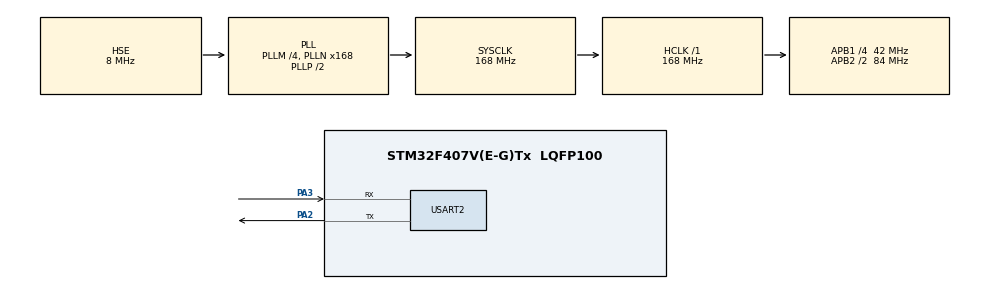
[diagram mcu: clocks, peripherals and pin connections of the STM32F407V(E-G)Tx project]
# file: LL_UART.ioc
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Mcu.Family=STM32F4
Mcu.Name=STM32F407V(E-G)Tx
Mcu.Package=LQFP100
NVIC.PriorityGroup=NVIC_PRIORITYGROUP_4
NVIC.USART2_IRQn=true\:0\:0\:false\:false\:true\:true\:true\:true
PA2.Mode=Asynchronous
PA2.Signal=USART2_TX
PA3.Mode=Asynchronous
PA3.Signal=USART2_RX
PH0-OSC_IN.Mode=HSE-External-Oscillator
PH0-OSC_IN.Signal=RCC_OSC_IN
PH1-OSC_OUT.Mode=HSE-External-Oscillator
PH1-OSC_OUT.Signal=RCC_OSC_OUT
ProjectManager.HeapSize=0x200
ProjectManager.StackSize=0x400
ProjectManager.TargetToolchain=STM32CubeIDE
RCC.48MHZClocksFreq_Value=84000000
RCC.AHBFreq_Value=168000000
RCC.APB1CLKDivider=RCC_HCLK_DIV4
RCC.APB1Freq_Value=42000000
RCC.APB1TimFreq_Value=84000000
RCC.APB2CLKDivider=RCC_HCLK_DIV2
RCC.APB2Freq_Value=84000000
RCC.APB2TimFreq_Value=168000000
RCC.CortexFreq_Value=168000000
RCC.HCLKFreq_Value=168000000
RCC.HSE_VALUE=8000000
RCC.HSI_VALUE=16000000
RCC.LSE_VALUE=32768
RCC.PLLM=4
RCC.PLLN=168
RCC.PLLSourceVirtual=RCC_PLLSOURCE_HSE
RCC.SYSCLKFreq_VALUE=168000000
RCC.SYSCLKSource=RCC_SYSCLKSOURCE_PLLCLK
RCC.VCOOutputFreq_Value=336000000
USART2.VirtualMode=VM_ASYNC
board=custom

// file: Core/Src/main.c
/* USER CODE BEGIN Header */
/**
  ******************************************************************************
  * @file           : main.c
  * @brief          : Main program body
  ******************************************************************************
  * @attention
  *
  * Copyright (c) 2023 STMicroelectronics.
  * All rights reserved.
  *
  * This software is licensed under terms that can be found in the LICENSE file
  * in the root directory of this software component.
  * If no LICENSE file comes with this software, it is provided AS-IS.
  *
  ******************************************************************************
  */
/* USER CODE END Header */
#include "main.h"
#include "usart.h"
#include "gpio.h"

/* USER CODE BEGIN Includes */
#include <stdio.h>
#include <string.h>
#include <lwrb.h>
#include <circularuart.h>
/* USER CODE END Includes */

/* USER CODE BEGIN PM */
#define RX_BUFFER_SIZE		30
#define TX_BUFFER_SIZE		100
/* USER CODE END PM */

/* USER CODE BEGIN PV */
uint8_t rx_buffer[RX_BUFFER_SIZE];
uint8_t	tx_buffer[TX_BUFFER_SIZE];
rbuart_t rb_tx;
rbuart_t rb_rx;
/* USER CODE END PV */

void SystemClock_Config(void);

/* USER CODE BEGIN 0 */
uint8_t UART2_SendData(uint8_t *pDta, uint32_t len, uint32_t timeout){
	uint32_t tickStar = HAL_GetTick();
	while((HAL_GetTick() - tickStar) < timeout){
		//verificar
		if(USART2->SR & USART_SR_TXE){
			//Eviar dato
			LL_USART_TransmitData8(USART2, *pDta);
			pDta++;
			len--;
		}
		if(len ==  0){
			return 0;
		}
	}
	return 1;
}

/* USER CODE END 0 */

int main(void)
{
  /* USER CODE BEGIN 1 */
	uint8_t txt[100];
	uint8_t rx[10];

  /* USER CODE END 1 */

  /* MCU Configuration--------------------------------------------------------*/

  /* Reset of all peripherals, Initializes the Flash interface and the Systick. */
  HAL_Init();

  /* Configure the system clock */
  SystemClock_Config();

  /* Initialize all configured peripherals */
  MX_GPIO_Init();
  MX_USART2_UART_Init();
  /* USER CODE BEGIN 2 */
  sprintf((char*)txt, "probando funcion\r\n");
//  UART2_SendData(txt, strlen((char*)txt), 1000);
  rbuart_init(&rb_tx, USART2, tx_buffer, TX_BUFFER_SIZE);
  rbuart_init(&rb_rx, USART2, rx_buffer, RX_BUFFER_SIZE);

  rbuart_send(&rb_tx, txt, strlen((char*)txt));
  rbuart_start_receive(&rb_rx);
  /* USER CODE END 2 */

  /* Infinite loop */
  while (1)
  {

    /* USER CODE BEGIN 3 */
	  if(rbuart_get_receiveSize(&rb_rx) >= 10){
		  rbuart_get_data(&rb_rx, rx, 5);
		  memset(txt, 0, 100);
		  sprintf((char*)txt, "datos recibidos->%s\r\n", rx);
		  rbuart_send(&rb_tx, txt, strlen((char*)txt));
	  }
  }
  /* USER CODE END 3 */
}

void SystemClock_Config(void)
{
  RCC_OscInitTypeDef RCC_OscInitStruct = {0};
  RCC_ClkInitTypeDef RCC_ClkInitStruct = {0};

  /** Configure the main internal regulator output voltage
  */
  __HAL_RCC_PWR_CLK_ENABLE();
  __HAL_PWR_VOLTAGESCALING_CONFIG(PWR_REGULATOR_VOLTAGE_SCALE1);

  /** Initializes the RCC Oscillators according to the specified parameters
  * in the RCC_OscInitTypeDef structure.
  */
  RCC_OscInitStruct.OscillatorType = RCC_OSCILLATORTYPE_HSE;
  RCC_OscInitStruct.HSEState = RCC_HSE_ON;
  RCC_OscInitStruct.PLL.PLLState = RCC_PLL_ON;
  RCC_OscInitStruct.PLL.PLLSource = RCC_PLLSOURCE_HSE;
  RCC_OscInitStruct.PLL.PLLM = 4;
  RCC_OscInitStruct.PLL.PLLN = 168;
  RCC_OscInitStruct.PLL.PLLP = RCC_PLLP_DIV2;
  RCC_OscInitStruct.PLL.PLLQ = 4;
  if (HAL_RCC_OscConfig(&RCC_OscInitStruct) != HAL_OK)
  {
    Error_Handler();
  }

  /** Initializes the CPU, AHB and APB buses clocks
  */
  RCC_ClkInitStruct.ClockType = RCC_CLOCKTYPE_HCLK|RCC_CLOCKTYPE_SYSCLK
                              |RCC_CLOCKTYPE_PCLK1|RCC_CLOCKTYPE_PCLK2;
  RCC_ClkInitStruct.SYSCLKSource = RCC_SYSCLKSOURCE_PLLCLK;
  RCC_ClkInitStruct.AHBCLKDivider = RCC_SYSCLK_DIV1;
  RCC_ClkInitStruct.APB1CLKDivider = RCC_HCLK_DIV4;
  RCC_ClkInitStruct.APB2CLKDivider = RCC_HCLK_DIV2;

  if (HAL_RCC_ClockConfig(&RCC_ClkInitStruct, FLASH_LATENCY_5) != HAL_OK)
  {
    Error_Handler();
  }
}

void Error_Handler(void)
{
  __disable_irq();
  while (1)
  {
  }
}
